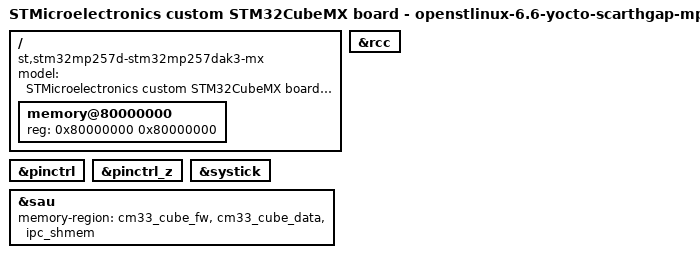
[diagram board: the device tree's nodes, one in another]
// SPDX-License-Identifier: (GPL-2.0-only OR BSD-3-Clause)
/*
 * Copyright (C) 2026, STMicroelectronics - All Rights Reserved
 * Author: STM32CubeMX code generation for STMicroelectronics.
 */

/* For more information on Device Tree configuration, please refer to
 * https://wiki.st.com/stm32mpu/wiki/Category:Device_tree_configuration
 */
/dts-v1/;
#include <dt-bindings/clock/stm32mp25-clksrc.h>
#include <dt-bindings/reset/st,stm32mp25-rcc.h>
#include <dt-bindings/pinctrl/stm32-pinfunc.h>
#include "stm32mp257.dtsi"
#include "stm32mp257d-stm32mp257dak3-mx-rcc.dtsi"
#include "stm32mp257d-stm32mp257dak3-mx-resmem.dtsi"
#include "stm32mp25xxai-pinctrl.dtsi"

/* USER CODE BEGIN includes */
/* USER CODE END includes */

/ {
	model = "STMicroelectronics custom STM32CubeMX board - openstlinux-6.6-yocto-scarthgap-mpu-v26.06.10";
	compatible = "st,stm32mp257d-stm32mp257dak3-mx", "st,stm32mp257";

	memory@80000000 {
		device_type = "memory";
		reg = <0x80000000 0x80000000>;

		/* USER CODE BEGIN memory */
		/* USER CODE END memory */
	};

	/* USER CODE BEGIN root */
	/* USER CODE END root */

}; /*root*/

&pinctrl {
	/* USER CODE BEGIN pinctrl */
	/* USER CODE END pinctrl */
};

&pinctrl_z {
	/* USER CODE BEGIN pinctrl_z */
	/* USER CODE END pinctrl_z */
};

&rcc {
	status = "okay";

	/* USER CODE BEGIN rcc */
	/* USER CODE END rcc */
};

&systick {
	status = "okay";

	/* USER CODE BEGIN systick */
	/* USER CODE END systick */
};

&sau {
	memory-region = <&cm33_cube_fw>, <&cm33_cube_data>, <&ipc_shmem>;
	status = "okay";

	/* USER CODE BEGIN sau */
	/* USER CODE END sau */
};

/* USER CODE BEGIN addons */
/* USER CODE END addons */

